# MCXN236 register map
Vendor: nxp.com; File version: 1.0
CPU: CM33 r2p0, little endian, MPU, FPU, VTOR, 3 interrupt priority bits
Registers are 32-bit, read-write, reset 0x0 unless marked. A register's access mark holds for its fields unless they carry their own. Offsets are from the block's base; [hi:lo] are bit positions; {n}, {i} and the like mark numbered series; 'fields as' and 'values as' point back to an identical list.

## ELS
Base 0x40054000
Same registers: ELS_ALIAS1 0x40055000, ELS_ALIAS2 0x40056000, ELS_ALIAS3 0x40057000
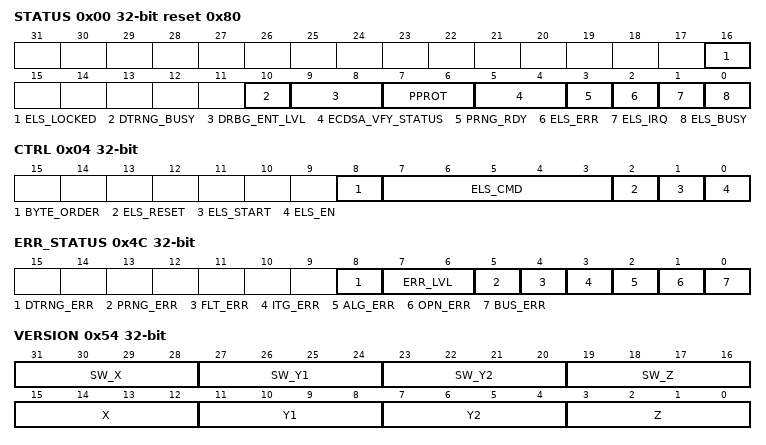
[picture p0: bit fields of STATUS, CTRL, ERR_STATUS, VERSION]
0x00 STATUS ro reset 0x80
  [16] ELS_LOCKED — When set, indicates that ELS is locked by a master
    0=Not locked by master; 1=Locked by master
  [10] DTRNG_BUSY — When set, it indicates TRNG is gathering entropy
    0=notent (Not gathering entropy); 1=ent (Gathering entropy)
  [9:8] DRBG_ENT_LVL — Entropy quality of the current DRBG instance
    0=none; 1=low (LOW, DRBG generates random numbers of low quality entropy); 2=HIGH, DRBG generates random numbers of high quality entropy
  [7:6] PPROT — Current command privilege level
    0=secnp (Secure, non-privileged); 1=secp (Secure, privileged); 2=nsecnp (Non-secure, non-privileged); 3=nsecp (Non-secure, privileged)
  [5:4] ECDSA_VFY_STATUS — Signature verify result status
    0=no_v_run (No verify run); 1=sig_fail (Signature verify failed); 2=sig_pass (Signature verify passed); 3=err (Invalid, Error)
  [3] PRNG_RDY — When set, indicates the internal PRNG is ready
    0=ntready (Internal PRNG not ready); 1=ready (Internal PRNG ready)
  [2] ELS_ERR — When set, indicates the ELS has detected an internal error
    0=nterr (Internal error not detected); 1=err (Internal error detected)
  [1] ELS_IRQ — When set, indicates the ELS has an active interrupt
    0=ntint (No active interrupt); 1=int (Active interrupt)
  [0] ELS_BUSY — When set, indicates the ELS is executing a crypto sequence
    0=ntcry (Crypto sequence not executing); 1=Crypto sequence executing
0x04 CTRL — Control Register
  [8] BYTE_ORDER — Defines endianness
    0=lit (Little endian); 1=big (Big endian)
  [7:3] ELS_CMD — ELS Command ID
  [2] ELS_RESET — Write to 1 to perform a ELS synchronous reset. Writing 0 has no effect.
  [1] ELS_START — Write to 1 to start an ELS operation. Writing 0 has no effect.
  [0] ELS_EN — ELS enable
    0=dis (Disabled); 1=en (Enabled)
0x08 CMDCFG0 — Command Configuration Register
  [31:0] CMDCFG0 — See
0x0C CFG — Configuration Register
  [25:16] ADCTRL — Maximum aes start delay
0x10 KIDX0 — Keystore Index 0 Register
  [4:0] KIDX0 — Keystore is indexed as an array of 128 bit key slots
0x14 KIDX1 — Keystore Index 1 Register
  [4:0] KIDX1 — Keystore is indexed as an array of 128 bit key slots
0x18 KPROPIN — Key Properties Request Register
  [31:0] KPROPIN — For commands that create a key - requested properties of the key that is being created
{0x20+8i} DMA_SRC{i} (i=0..2) — DMA Source {i} Register
  [31:0] ADDR_SRC{i} — Defines the system address of the start of the data to be transferred to the ELS via DMA
0x24 DMA_SRC0_LEN — DMA Source 0 Length Register
  [31:0] SIZE_SRC0_LEN — Size in bytes of the data to be transferred from the target defined in SFR DMA_SRC0
0x34 DMA_SRC2_LEN — DMA Source 2 Length Register
  [31:0] SIZE_SRC2_LEN — Size in bytes of the data to be transferred from the target defined in SFR DMA_SRC2
0x38 DMA_RES0 — DMA Result 0 Register
  [31:0] ADDR_RES0 — Defines the system start address where the result of the ELS operation is transferred via DMA
0x3C DMA_RES0_LEN — DMA Result 0 Size Register
  [31:0] SIZE_RES0_LEN — Size in bytes of the data to be transferred
0x40 INT_ENABLE — Interrupt Enable Register
  [0] INT_EN — Interrupt enable bit
0x44 INT_STATUS_CLR wo — Interrupt Status Clear Register
  [0] INT_CLR — Interrupt status clear
0x48 INT_STATUS_SET wo — Interrupt Status Set Register
  [0] INT_SET — Sets interrupt by software
0x4C ERR_STATUS ro — Error Status Register
  [8] DTRNG_ERR — TRNG unable to gather entropy with the current configuration
  [7:6] ERR_LVL — Indicates the triggered error level: 0, 1 ,2
  [5] PRNG_ERR — User read of PRNG_DATOUT when STATUS[PRNG_RDY] is 0
  [4] FLT_ERR — Indicates hardware fault error: attempt to change the value of an internal register
  [3] ITG_ERR — Indicates data integrity error: internal data integrity check failed
  [2] ALG_ERR — Indicates algorithm error: an internal algorithm has produced an unexpected result
  [1] OPN_ERR — Indicates operational error: ELS has been incorrectly operated
  [0] BUS_ERR — Indicates bus access error: public or private bus
0x50 ERR_STATUS_CLR wo — Error Status Clear Register
  [0] ERR_CLR
    0=Exits ELS error state; 1=clr (Clears ELS error status bits)
0x54 VERSION ro
  [31:28] SW_X — Software major release version: possible values are from 1-9
  [27:24] SW_Y1 — Software minor release version digit1: possible values are from 0-9
  [23:20] SW_Y2 — Software minor release version digit0: possible values are from 0-9
  [19:16] SW_Z — Software extended revision version: possible values are from 0-9
  [15:12] X — Major release version: possible values are from 1-9
  [11:8] Y1 — Minor release version digit1: possible values are from 0-9
  [7:4] Y2 — Minor release version digit0: possible values are from 0-9
  [3:0] Z — Extended release version digit1: possible values are from 0-9
0x5C PRNG_DATOUT ro reset not defined — PRNG SW Read Out Register
  [31:0] PRNG_DATOUT — 32-bit wide pseudo-random number
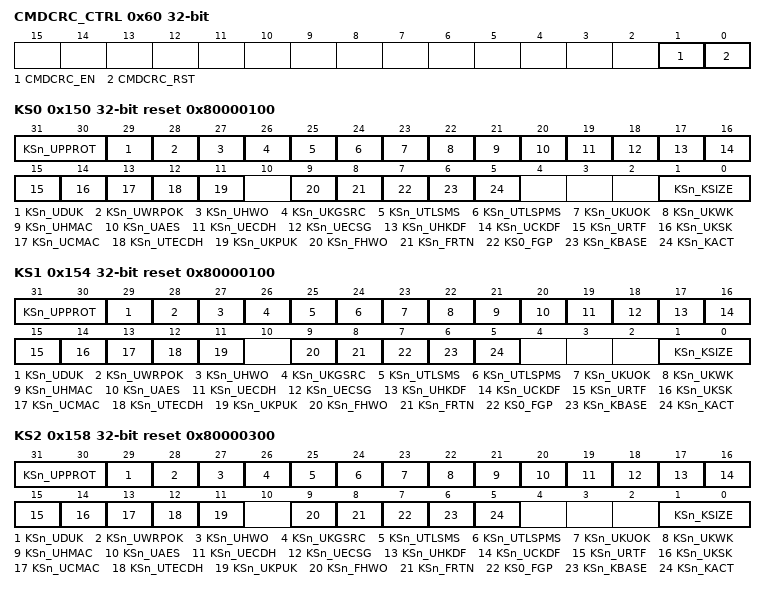
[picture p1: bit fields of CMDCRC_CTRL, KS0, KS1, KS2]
0x60 CMDCRC_CTRL — CRC Configuration Register
  [1] CMDCRC_EN — CRC enable bit
  [0] CMDCRC_RST — CRC reset to initial value
0x64 CMDCRC ro reset 0xA5A5A5A5 — Command CRC Value Register
  [31:0] CMDCRC — Current CRC value
0x68 SESSION_ID reset 0xCE2C6AF1
0x70 DMA_FIN_ADDR ro — Final DMA Address Register
  [31:0] DMA_FIN_ADDR — Final AHB address presented by ELS DMA to the system
0x74 MASTER_ID reset 0x1F
  [4:0] MASTER_ID — High Priviledge Master ID
0x78 KIDX2 — Keystore Index 2 Register
  [4:0] KIDX2 — Keystore is indexed as an array of 128 bit key slots
0x150 KS0 ro reset 0x80000100 — Status Register
  [31:30] KSn_UPPROT — Indicates privilege level key. User access rights are required to use this key.
    0=nps (Non-privileged, secure); 1=npns (Non-privileged, non-secure); 2=ps (Privileged, secure); 3=pns (Privileged, non-secure)
  [29] KSn_UDUK — Indicates device unique key whose value is unique per die, and secret, that is, not known outside of CSS
    0=ndk (Key is not a device unique key); 1=dk (Key is a device unique key)
  [28] KSn_UWRPOK — Indicates wrap key that can be RFC3394 wrapped by another keystore key.
    0=nwr (Key cannot be RFC3394 wrapped); 1=wr (Key can be RFC3394 wrapped)
  [27] KSn_UHWO — Indicates hardware out key that only exists in a hardware out slot, that is a slot that has status bit FHWO set
    0=anys (Key can exist in any slot); 1=hs (Key can only exist in a hardware out slot)
  [26] KSn_UKGSRC — Supplies key material source for deterministic ECC KEYGEN
    0=nms (Key cannot be used as a key material source for deterministic ECC keygen); 1=ms (Key can be used as a key material source for deterministic ECC keygen)
  [25] KSn_UTLSMS — Indicates TLS master secret key that is used as the input key to the TLS_INIT command with input parameter "FINALIZE" set to 1
    0=ntls (Key is not a TLS master secret key); 1=tls (Key is a TLS master secret key)
  [24] KSn_UTLSPMS — Indicates TLS pre master secret key that is used as the input key to the TLS_INIT command with input parameter "FINALIZE" set to 0
    0=ntlsp (Key is not a TLS pre master secret key); 1=tlsp (Key is a TLS pre master secret key)
  [23] KSn_UKUOK — Indicates RFC3394 key unwrap only Key that is used as the unwrapping key for the KEYIN(RFC3394=true) command, but not as the wrapping key for the KEYOUT command
    0=nrfc (Key is not a RFC3394 key unwrap only key); 1=rfc (Key is a RFC3394 key unwrap only key)
  [22] KSn_UKWK — Indicates RFC3394 key wrap and unwrap key that is used as the unwrapping key for the KEYIN(RFC3394=true) command, and as the wrapping key for the KEYOUT command
    0=nrfcw (Key is not a RFC3394 key wrap plus unwrap only key); 1=rfcw (Key is a RFC3394 key wrap plus unwrap only key)
  [21] KSn_UHMAC — Indicates HMAC key that is used as the input key for the HMAC command.
    0=nhmac (Key is not a HMAC key); 1=hmac (Key is a HMAC key)
  [20] KSn_UAES — Indicates AES key that is used as the input key for the CIPHER or AUTH_CIPHER commands.
    0=naes (Key is not a AES key); 1=aes (Key is a AES key)
  [19] KSn_UECDH — Indicates Diffie Hellman key exchange private key that is used as the input private key for the ECKXCH command
    0=ndh (Key is not a Diffie hellman key exchange private key); 1=dh (Key is a Diffie hellman key exchange private key)
  [18] KSn_UECSG — Indicates ECC signing key that is used as the input private key for the ECSIGN command.
    0=necc (Key is not a ECC signing key); 1=ecc (Key is a ECC signing key)
  [17] KSn_UHKDF — Indicates HKDF key that is used as the input key for the HKDF command.
    0=nhkdf (Key is not a HKDF key); 1=hkdf (Key is a HKDF key)
  [16] KSn_UCKDF — Indicates CMAC based derivation key that is used as the input key for the CKDF command.
    0=ncmac (Key is not a CMAC based derivation key); 1=cmac (Key is a CMAC based derivation key)
  [15] KSn_URTF — Indicates ECC signing key that is used as the input private key to the ECSIGN command when SIGNRTF command parameter is set
    0=nsrtf (Key is not a ECC signing key that can be used as the input private key to ECSIGN command when SIGNRTF command parameter is set); 1=srtf (Key is a ECC signing key that can be used as the input private key to ECSIGN command when SIGNRTF command parameter is set)
  [14] KSn_UKSK — Indicates public key signing key that is used to sign the ECC public key generated by the KEYGEN command
    0=necc (Key is not a public key signing Key); 1=ecc (Key is a public key signing key)
  [13] KSn_UCMAC — Indicates CMAC key that is used as input key for the CMAC command.
    0=ncm (Key is not a CMAC key); 1=cm (Key is a CMAC key)
  [12] KSn_UTECDH — Indicates a private key that can be only used with a trusted public key (key with UKPUK=1)
    0=ntech (Key is not a UTECDH key); 1=tech (Key is a UTECDH key)
  [11] KSn_UKPUK — Indicates trusted public key that can be used as the public key in an ECSIGN command in which the private key is a UTECDH key
    0=ntstd (Key is not a trusted public key); 1=tstd (Key is a trusted public key)
  [9] KSn_FHWO — Indicates the hardware out type key slot. See UHWO.
    0=nhwsl (Slot is not a hardware out type key slot); 1=hwsl (Slot is a hardware out type key slot)
  [8] KSn_FRTN — Specifies the retention type key slot
    0=nrtn (Slot is not a retention type key slot); 1=rtn (Slot is a retention type key slot)
  [7] KS0_FGP — Specifies the general purpose type key slot
    0=ngen (Slot is not a general purpose type key slot); 1=gen (Slot is a general purpose type key slot)
  [6] KSn_KBASE — Indicates the base key slot of a multi-slot key.
    0=nbslt (Key is not a base slot of a multi slot key); 1=bslt (Key is a base slot of a multi slot key)
  [5] KSn_KACT — Indicates that a slot is in use by a key.
    0=nslt (Key slot is not in use by a key); 1=slt (Key is in use by a key)
  [1:0] KSn_KSIZE — Indicates the key size
    0=size128 (Key size is 128 bits (1 slot)); 1=slot2 (Key size is 256 bits (2 slots)); 3=size256 (Key size is 512 bits (4 slots))
0x154 KS1 ro reset 0x80000100 — Status Register
  fields as KS0
0x158 KS2 ro reset 0x80000300 — Status Register
  fields as KS0
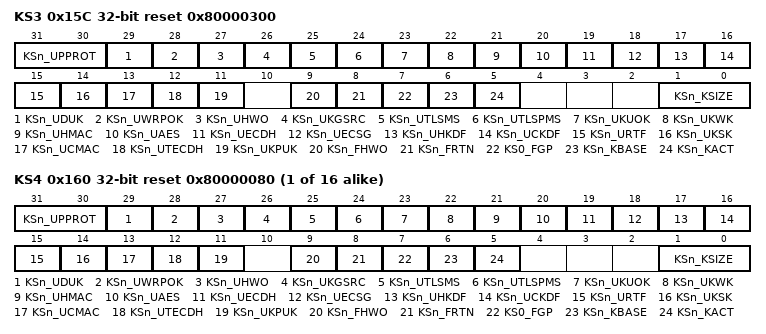
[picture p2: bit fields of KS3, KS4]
0x15C KS3 ro reset 0x80000300 — Status Register
  fields as KS0
{0x150+4i} KS{i} ro reset 0x80000080 (i=4..19) — Status Register
  fields as KS0
